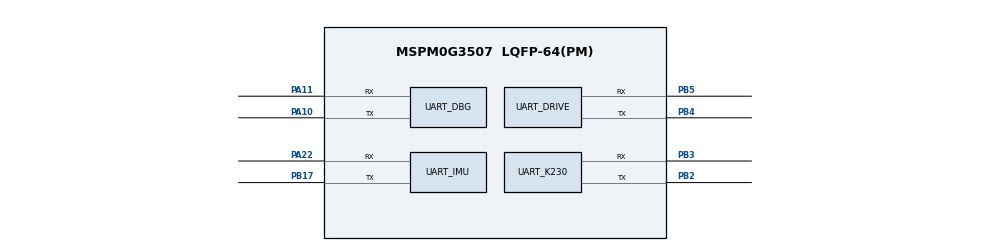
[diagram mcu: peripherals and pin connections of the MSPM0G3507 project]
/**
 * These arguments were used when this file was generated. They will be automatically applied on subsequent loads
 * via the GUI or CLI. Run CLI with '--help' for additional information on how to override these arguments.
 */
//@cliArgs --device "MSPM0G350X" --package "LQFP-64(PM)" --part "Default"
//@v2CliArgs --device "MSPM0G3507" --package "LQFP-64(PM)"
// @cliArgs --board /ti/boards/LP_MSPM0G3507 --rtos nortos

const SYSCTL = scripting.addModule("/ti/driverlib/SYSCTL");
const Board   = scripting.addModule("/ti/driverlib/Board", {}, false);

SYSCTL.forceDefaultClkConfig = true;
SYSCTL.clockTreeEn           = true;

const UART = scripting.addModule("/ti/driverlib/UART", {}, false);

// USART0: 调试口
const UART_DBG = UART.addInstance();
UART_DBG.$name                  = "DEBUG_UART";
UART_DBG.targetBaudRate         = 115200;
UART_DBG.enableFIFO             = true;
UART_DBG.peripheral.$assign     = "UART0";
UART_DBG.peripheral.txPin.$assign = "PA10";
UART_DBG.peripheral.rxPin.$assign = "PA11";

// USART1: 四驱
const UART_DRIVE = UART.addInstance();
UART_DRIVE.$name                  = "DRIVE_UART";
UART_DRIVE.targetBaudRate         = 115200;
UART_DRIVE.enableFIFO             = true;
UART_DRIVE.peripheral.$assign     = "UART1";
UART_DRIVE.peripheral.txPin.$assign = "PB4";
UART_DRIVE.peripheral.rxPin.$assign = "PB5";

// USART2: 陀螺仪(MPU)
const UART_IMU = UART.addInstance();
UART_IMU.$name                  = "IMU_UART";
UART_IMU.targetBaudRate         = 115200;
UART_IMU.enableFIFO             = true;
UART_IMU.enabledInterrupts      = ["RX"];
UART_IMU.rxFifoThreshold        = "DL_UART_RX_FIFO_LEVEL_1_2_FULL";
UART_IMU.peripheral.$assign     = "UART2";
UART_IMU.peripheral.txPin.$assign = "PB17";
UART_IMU.peripheral.rxPin.$assign = "PA22";

// USART3: K230
const UART_K230 = UART.addInstance();
UART_K230.$name                  = "K230_UART";
UART_K230.targetBaudRate         = 115200;
UART_K230.enableFIFO             = true;
UART_K230.peripheral.$assign     = "UART3";
UART_K230.peripheral.txPin.$assign = "PB2";
UART_K230.peripheral.rxPin.$assign = "PB3";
